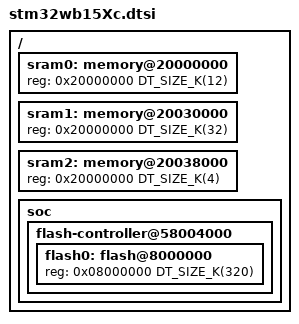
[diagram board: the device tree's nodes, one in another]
/*
 * Copyright (c) 2018 Linaro Limited
 *
 * SPDX-License-Identifier: Apache-2.0
 */
#include <mem.h>
#include <st/wb/stm32wb15.dtsi>

/ {
	sram0: memory@20000000 {
		reg = <0x20000000 DT_SIZE_K(12)>;
	};

	sram1: memory@20030000 {
		reg = <0x20000000 DT_SIZE_K(32)>;
	};

	sram2: memory@20038000 {
		reg = <0x20000000 DT_SIZE_K(4)>;
	};

	soc {
		flash-controller@58004000 {
			flash0: flash@8000000 {
				reg = <0x08000000 DT_SIZE_K(320)>;
			};
		};
	};
};
